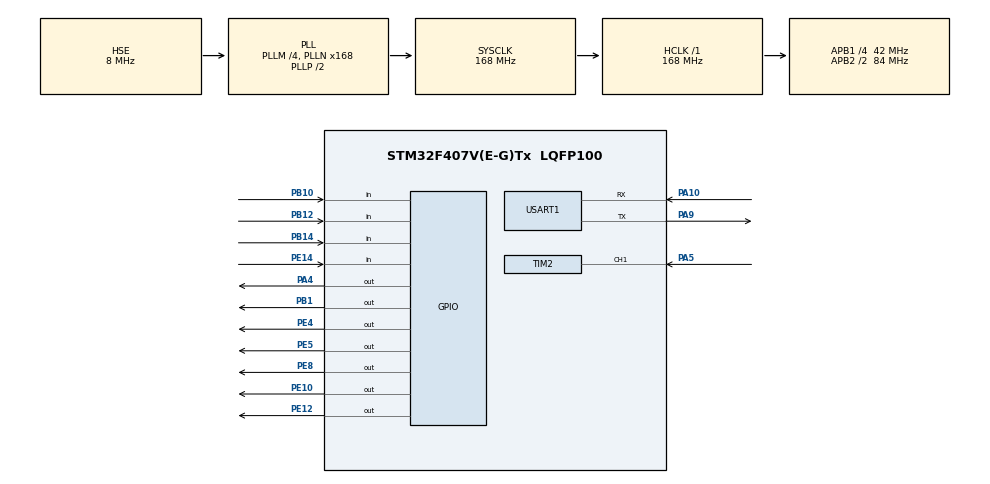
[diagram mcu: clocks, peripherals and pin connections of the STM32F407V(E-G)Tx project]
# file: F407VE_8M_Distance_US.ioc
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Mcu.Family=STM32F4
PE12.GPIO_ModeDefaultOutputPP=GPIO_MODE_OUTPUT_PP
PE8.PinState=GPIO_PIN_SET
PH0-OSC_IN.Signal=RCC_OSC_IN
PE4.GPIO_ModeDefaultOutputPP=GPIO_MODE_OUTPUT_PP
RCC.CortexFreq_Value=168000000
TIM2.Channel-Input_Capture1_from_TI1=TIM_CHANNEL_1
PB10.GPIO_PuPd=GPIO_PULLDOWN
PE8.GPIO_PuPd=GPIO_PULLUP
PE10.GPIO_PuPd=GPIO_PULLUP
RCC.SYSCLKSource=RCC_SYSCLKSOURCE_PLLCLK
ProjectManager.StackSize=0x400
TIM2.ICPolarity_CH1=TIM_INPUTCHANNELPOLARITY_BOTHEDGE
PE5.GPIO_PuPd=GPIO_PULLUP
PB1.GPIO_PuPd=GPIO_PULLUP
RCC.HCLKFreq_Value=168000000
RCC.APB2TimFreq_Value=168000000
PE5.Signal=GPIO_Output
RCC.AHBFreq_Value=168000000
PH0-OSC_IN.Mode=HSE-External-Oscillator
RCC.HSE_VALUE=8000000
PA4.GPIO_PuPd=GPIO_PULLDOWN
PA4.GPIO_Speed=GPIO_SPEED_FREQ_VERY_HIGH
PC14-OSC32_IN.Mode=LSE-External-Oscillator
PB1.GPIO_Speed=GPIO_SPEED_FREQ_VERY_HIGH
PA14.Mode=Serial_Wire
PE4.GPIO_Speed=GPIO_SPEED_FREQ_VERY_HIGH
PA5.GPIO_PuPd=GPIO_PULLDOWN
NVIC.TIM2_IRQn=true\:0\:0\:false\:false\:true\:true\:true
PE5.PinState=GPIO_PIN_SET
PE10.GPIO_ModeDefaultOutputPP=GPIO_MODE_OUTPUT_PP
PE10.GPIO_Speed=GPIO_SPEED_FREQ_VERY_HIGH
PE10.Signal=GPIO_Output
PE4.Signal=GPIO_Output
PB1.PinState=GPIO_PIN_SET
PH1-OSC_OUT.Mode=HSE-External-Oscillator
PB12.GPIO_Mode=GPIO_MODE_INPUT
Mcu.Package=LQFP100
TIM2.Prescaler=83
PB1.Signal=GPIO_Output
PB14.GPIO_PuPd=GPIO_PULLDOWN
PA10.Signal=USART1_RX
PE12.GPIO_Speed=GPIO_SPEED_FREQ_VERY_HIGH
PE8.GPIO_Speed=GPIO_SPEED_FREQ_VERY_HIGH
RCC.APB2CLKDivider=RCC_HCLK_DIV2
RCC.APB1TimFreq_Value=84000000
PE8.GPIO_ModeDefaultOutputPP=GPIO_MODE_OUTPUT_PP
PE14.GPIO_Mode=GPIO_MODE_INPUT
NVIC.USART1_IRQn=true\:0\:0\:false\:false\:true\:true\:true
PE12.GPIO_PuPd=GPIO_PULLUP
PE10.PinState=GPIO_PIN_SET
RCC.PLLSourceVirtual=RCC_PLLSOURCE_HSE
PC15-OSC32_OUT.Mode=LSE-External-Oscillator
PA10.Mode=Asynchronous
RCC.APB1CLKDivider=RCC_HCLK_DIV4
PC14-OSC32_IN.Signal=RCC_OSC32_IN
PA13.Signal=SYS_JTMS-SWDIO
PA9.Mode=Asynchronous
PB10.GPIO_Mode=GPIO_MODE_INPUT
PA4.PinState=GPIO_PIN_RESET
ProjectManager.TargetToolchain=MDK-ARM V5.27
PA9.Signal=USART1_TX
PC15-OSC32_OUT.Signal=RCC_OSC32_OUT
PB10.Signal=GPIO_Input
PB14.Signal=GPIO_Input
PA5.Signal=S_TIM2_CH1_ETR
board=custom
RCC.VCOOutputFreq_Value=336000000
RCC.APB2Freq_Value=84000000
PE14.Signal=GPIO_Input
VP_TIM2_VS_ClockSourceINT.Mode=Internal
PE8.Signal=GPIO_Output
PH1-OSC_OUT.Signal=RCC_OSC_OUT
PE14.GPIO_PuPd=GPIO_PULLDOWN
TIM2.Period=0xffff
PA13.Mode=Serial_Wire
Mcu.Name=STM32F407V(E-G)Tx
PE12.Signal=GPIO_Output
PE4.GPIO_PuPd=GPIO_PULLUP
PE12.PinState=GPIO_PIN_SET
RCC.48MHZClocksFreq_Value=84000000
PA4.Signal=GPIO_Output
RCC.SYSCLKFreq_VALUE=168000000
USART1.VirtualMode=VM_ASYNC
SH.S_TIM2_CH1_ETR.0=TIM2_CH1,Input_Capture1_from_TI1
PA14.Signal=SYS_JTCK-SWCLK
ProjectManager.HeapSize=0x200
PE5.GPIO_ModeDefaultOutputPP=GPIO_MODE_OUTPUT_PP
RCC.HSI_VALUE=16000000
PA5.GPIO_Speed=GPIO_SPEED_FREQ_VERY_HIGH
NVIC.PriorityGroup=NVIC_PRIORITYGROUP_4
RCC.PLLM=4
RCC.PLLN=168
PE5.GPIO_Speed=GPIO_SPEED_FREQ_VERY_HIGH
TIM2.AutoReloadPreload=TIM_AUTORELOAD_PRELOAD_ENABLE
PE4.PinState=GPIO_PIN_SET
PB1.GPIO_ModeDefaultOutputPP=GPIO_MODE_OUTPUT_PP
PB12.GPIO_PuPd=GPIO_PULLDOWN
RCC.APB1Freq_Value=42000000
PB14.GPIO_Mode=GPIO_MODE_INPUT
PB12.Signal=GPIO_Input

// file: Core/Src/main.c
/* USER CODE BEGIN Header */
/**
  ******************************************************************************
  * @file           : main.c
  * @brief          : Main program body
  ******************************************************************************
  * @attention
  *
  * <h2><center>&copy; Copyright (c) 2020 STMicroelectronics.
  * All rights reserved.</center></h2>
  *
  * This software component is licensed by ST under BSD 3-Clause license,
  * the "License"; You may not use this file except in compliance with the
  * License. You may obtain a copy of the License at:
  *                        opensource.org/licenses/BSD-3-Clause
  *
  ******************************************************************************
  */
/* USER CODE END Header */
#include "main.h"
#include "tim.h"
#include "usart.h"
#include "gpio.h"

/* USER CODE BEGIN Includes */
#include "DELAY/delay.h"
#include "DIST_US/dist_us.h"
#include "USART/myusart1.h"
#include "OLED/oled_iic.h"
#include "stdio.h"
/* USER CODE END Includes */

/* USER CODE BEGIN PV */
uint8_t str[10];
/* USER CODE END PV */

void SystemClock_Config(void);

int main(void)
{

  /* MCU Configuration--------------------------------------------------------*/

  /* Reset of all peripherals, Initializes the Flash interface and the Systick. */
  HAL_Init();

  /* Configure the system clock */
  SystemClock_Config();

  /* Initialize all configured peripherals */
  MX_GPIO_Init();
  MX_USART1_UART_Init();
  MX_TIM2_Init();
  /* USER CODE BEGIN 2 */
  Delay_Init(168);
  MyUSART1_Init();
  OLED_Init();

  /* USER CODE END 2 */

  /* Infinite loop */
  while (1)
  {

    /* USER CODE BEGIN 3 */
    Delay_ms(100);
    OLED_CLS();
    OLED_ShowFloat(1,1,Dist_US_GetDistF(),TEXTSIZE_BIG,REVERSE_OFF);
    sprintf(str,"%d",Dist_US_GetDistI());
    MyUSART1_WriteLine(str);
  }
  /* USER CODE END 3 */
}

void SystemClock_Config(void)
{
  RCC_OscInitTypeDef RCC_OscInitStruct = {0};
  RCC_ClkInitTypeDef RCC_ClkInitStruct = {0};

  /** Configure the main internal regulator output voltage
  */
  __HAL_RCC_PWR_CLK_ENABLE();
  __HAL_PWR_VOLTAGESCALING_CONFIG(PWR_REGULATOR_VOLTAGE_SCALE1);
  /** Initializes the RCC Oscillators according to the specified parameters
  * in the RCC_OscInitTypeDef structure.
  */
  RCC_OscInitStruct.OscillatorType = RCC_OSCILLATORTYPE_HSE;
  RCC_OscInitStruct.HSEState = RCC_HSE_ON;
  RCC_OscInitStruct.PLL.PLLState = RCC_PLL_ON;
  RCC_OscInitStruct.PLL.PLLSource = RCC_PLLSOURCE_HSE;
  RCC_OscInitStruct.PLL.PLLM = 4;
  RCC_OscInitStruct.PLL.PLLN = 168;
  RCC_OscInitStruct.PLL.PLLP = RCC_PLLP_DIV2;
  RCC_OscInitStruct.PLL.PLLQ = 4;
  if (HAL_RCC_OscConfig(&RCC_OscInitStruct) != HAL_OK)
  {
    Error_Handler();
  }
  /** Initializes the CPU, AHB and APB buses clocks
  */
  RCC_ClkInitStruct.ClockType = RCC_CLOCKTYPE_HCLK|RCC_CLOCKTYPE_SYSCLK
                              |RCC_CLOCKTYPE_PCLK1|RCC_CLOCKTYPE_PCLK2;
  RCC_ClkInitStruct.SYSCLKSource = RCC_SYSCLKSOURCE_PLLCLK;
  RCC_ClkInitStruct.AHBCLKDivider = RCC_SYSCLK_DIV1;
  RCC_ClkInitStruct.APB1CLKDivider = RCC_HCLK_DIV4;
  RCC_ClkInitStruct.APB2CLKDivider = RCC_HCLK_DIV2;

  if (HAL_RCC_ClockConfig(&RCC_ClkInitStruct, FLASH_LATENCY_5) != HAL_OK)
  {
    Error_Handler();
  }
}

void Error_Handler(void)
{
}

/************************ (C) COPYRIGHT STMicroelectronics *****END OF FILE****/
